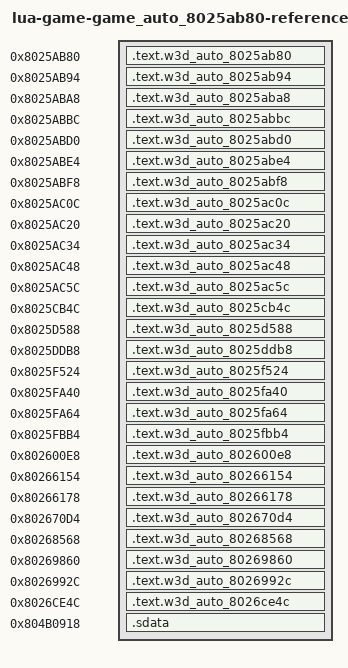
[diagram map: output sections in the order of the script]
/* Generated reference-only placements. All bodies are source-built. */
OUTPUT_FORMAT("elf32-powerpc")
OUTPUT_ARCH(powerpc)
ENTRY(w3d_auto_8025ab80)
_SDA_BASE_ = 0x804b2540;
_SDA2_BASE_ = 0x804c2540;
fn_8015F5A0 = 0x8015f5a0;
fn_8015FD1C = 0x8015fd1c;
fn_80162024 = 0x80162024;
fn_80165254 = 0x80165254;
fn_8025CBE0 = 0x8025cbe0;
fn_8025D020 = 0x8025d020;
fn_8026026C = 0x8026026c;
fn_8026857C = 0x8026857c;
fn_802B0668 = 0x802b0668;
fn_802B0FEC = 0x802b0fec;
fn_802B15E0 = 0x802b15e0;
fn_802B1BD0 = 0x802b1bd0;
fn_802B1F98 = 0x802b1f98;
fn_802B2344 = 0x802b2344;
SECTIONS {
  .text.w3d_auto_8025ab80 0x8025ab80 : { *(.text.w3d_auto_8025ab80) }
  .text.w3d_auto_8025ab94 0x8025ab94 : { *(.text.w3d_auto_8025ab94) }
  .text.w3d_auto_8025aba8 0x8025aba8 : { *(.text.w3d_auto_8025aba8) }
  .text.w3d_auto_8025abbc 0x8025abbc : { *(.text.w3d_auto_8025abbc) }
  .text.w3d_auto_8025abd0 0x8025abd0 : { *(.text.w3d_auto_8025abd0) }
  .text.w3d_auto_8025abe4 0x8025abe4 : { *(.text.w3d_auto_8025abe4) }
  .text.w3d_auto_8025abf8 0x8025abf8 : { *(.text.w3d_auto_8025abf8) }
  .text.w3d_auto_8025ac0c 0x8025ac0c : { *(.text.w3d_auto_8025ac0c) }
  .text.w3d_auto_8025ac20 0x8025ac20 : { *(.text.w3d_auto_8025ac20) }
  .text.w3d_auto_8025ac34 0x8025ac34 : { *(.text.w3d_auto_8025ac34) }
  .text.w3d_auto_8025ac48 0x8025ac48 : { *(.text.w3d_auto_8025ac48) }
  .text.w3d_auto_8025ac5c 0x8025ac5c : { *(.text.w3d_auto_8025ac5c) }
  .text.w3d_auto_8025cb4c 0x8025cb4c : { *(.text.w3d_auto_8025cb4c) }
  .text.w3d_auto_8025d588 0x8025d588 : { *(.text.w3d_auto_8025d588) }
  .text.w3d_auto_8025ddb8 0x8025ddb8 : { *(.text.w3d_auto_8025ddb8) }
  .text.w3d_auto_8025f524 0x8025f524 : { *(.text.w3d_auto_8025f524) }
  .text.w3d_auto_8025fa40 0x8025fa40 : { *(.text.w3d_auto_8025fa40) }
  .text.w3d_auto_8025fa64 0x8025fa64 : { *(.text.w3d_auto_8025fa64) }
  .text.w3d_auto_8025fbb4 0x8025fbb4 : { *(.text.w3d_auto_8025fbb4) }
  .text.w3d_auto_802600e8 0x802600e8 : { *(.text.w3d_auto_802600e8) }
  .text.w3d_auto_80266154 0x80266154 : { *(.text.w3d_auto_80266154) }
  .text.w3d_auto_80266178 0x80266178 : { *(.text.w3d_auto_80266178) }
  .text.w3d_auto_802670d4 0x802670d4 : { *(.text.w3d_auto_802670d4) }
  .text.w3d_auto_80268568 0x80268568 : { *(.text.w3d_auto_80268568) }
  .text.w3d_auto_80269860 0x80269860 : { *(.text.w3d_auto_80269860) }
  .text.w3d_auto_8026992c 0x8026992c : { *(.text.w3d_auto_8026992c) }
  .text.w3d_auto_8026ce4c 0x8026ce4c : { *(.text.w3d_auto_8026ce4c) }
  .sdata 0x804b0918 (NOLOAD) : {
    . = 0x0; lbl_804B0918 = .;
    . = 0x8; lbl_804B0920 = .;
    . = 0x10; lbl_804B0928 = .;
    . = 0x18; lbl_804B0930 = .;
    . = 0x20; lbl_804B0938 = .;
    . = 0x28; lbl_804B0940 = .;
    . = 0x30; lbl_804B0948 = .;
    . = 0x38; lbl_804B0950 = .;
    . = 0xe70; lbl_804B1788 = .;
    . += 1; }
  /DISCARD/ : { *(.text*) *(.rodata*) *(.data*) *(.bss*) *(.sdata*) *(.sbss*) *(.comment) }
}
